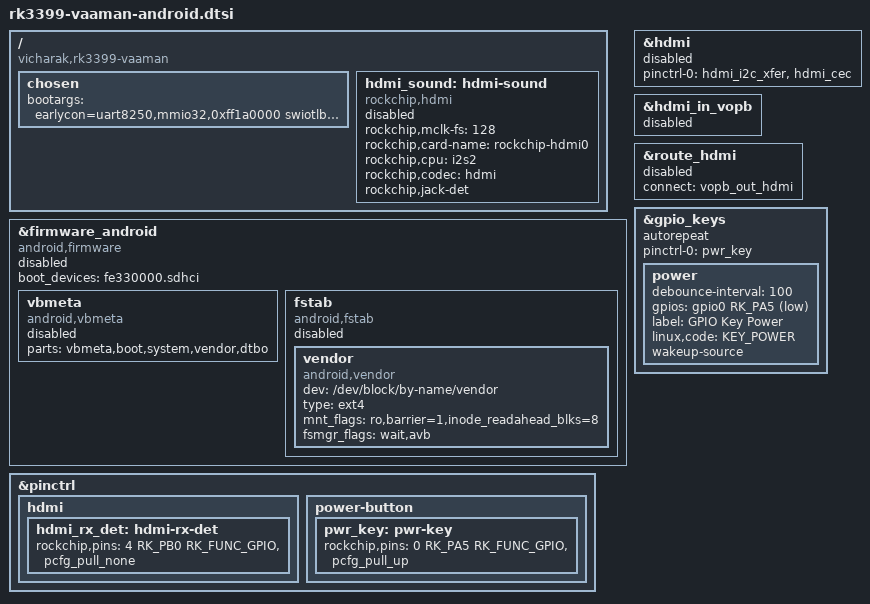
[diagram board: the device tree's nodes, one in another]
// SPDX-License-Identifier: (GPL-2.0+ OR MIT)
/*
 * Copyright (C) 2023 Vicharak India
 */

#include "rk3399-vaaman.dtsi"
#include "rk3399-android.dtsi"

&firmware_android {
	status = "disabled";
	compatible = "android,firmware";
	boot_devices = "fe330000.sdhci";

	vbmeta {
		status = "disabled";
		compatible = "android,vbmeta";
		parts = "vbmeta,boot,system,vendor,dtbo";
	};

	fstab {
		status = "disabled";
		compatible = "android,fstab";

		vendor {
			compatible = "android,vendor";
			dev = "/dev/block/by-name/vendor";
			type = "ext4";
			mnt_flags = "ro,barrier=1,inode_readahead_blks=8";
			fsmgr_flags = "wait,avb";
		};
	};
};


/ {
	compatible = "vicharak,rk3399-vaaman", "rockchip,rk3399";

	/delete-node/ chosen;

	chosen {
		bootargs = "earlycon=uart8250,mmio32,0xff1a0000 swiotlb=1 console=ttyFIQ0 androidboot.baseband=N/A androidboot.veritymode=enforcing androidboot.hardware=rk30board androidboot.console=ttyFIQ0 init=/init initrd=0x62000001,0x00800000 coherent_pool=1m";
	};

	// HDMI Sound: {{{
	hdmi_sound: hdmi-sound {
		compatible = "rockchip,hdmi";
		rockchip,mclk-fs = <128>;
		rockchip,card-name = "rockchip-hdmi0";
		rockchip,cpu = <&i2s2>;
		rockchip,codec = <&hdmi>;
		rockchip,jack-det;
		status = "disabled";
	};
	// End of HDMI Sound }}}
};

// HDMI: {{{
&hdmi {
	pinctrl-names = "default";
	pinctrl-0 = <&hdmi_i2c_xfer>, <&hdmi_cec>;
	#address-cells = <1>;
	#size-cells = <0>;
	#sound-dai-cells = <0>;
	status = "disabled";
};

&hdmi_in_vopb {
	status = "disabled";
};

&route_hdmi {
	connect = <&vopb_out_hdmi>;
	status = "disabled";
};

&hdmi_sound {
	status = "disabled";
};
// End of HDMI }}}

&pinctrl {
	// HDMI: {{{
	hdmi {
		hdmi_rx_det: hdmi-rx-det {
			rockchip,pins =
				<4 RK_PB0 RK_FUNC_GPIO &pcfg_pull_none>;
		};
	};
	// Endi of HDMI }}}

	// Power Button: {{{
	power-button {
		pwr_key: pwr-key {
			rockchip,pins = <0 RK_PA5 RK_FUNC_GPIO &pcfg_pull_up>;
		};
	};
	// End of Power Button }}}
};

// Power Button: {{{
&gpio_keys {
    status = "okay";
    autorepeat;
	pinctrl-names = "default";
	pinctrl-0 = <&pwr_key>;

	power {
		debounce-interval = <100>;
		gpios = <&gpio0 RK_PA5 GPIO_ACTIVE_LOW>;
		label = "GPIO Key Power";
		linux,code = <KEY_POWER>;
		wakeup-source;
	};
};
// End of Power Button }}}
